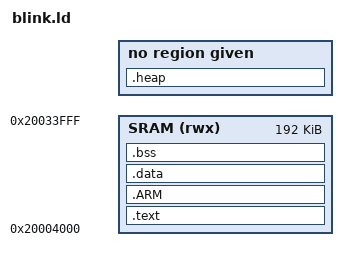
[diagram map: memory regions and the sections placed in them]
/*
 *  Copyright (c) 2015, Parse, LLC. All rights reserved.
 *
 *  You are hereby granted a non-exclusive, worldwide, royalty-free license to use,
 *  copy, modify, and distribute this software in source code or binary form for use
 *  in connection with the web services and APIs provided by Parse.
 *
 *  As with any software that integrates with the Parse platform, your use of
 *  this software is subject to the Parse Terms of Service
 *  [https://www.parse.com/about/terms]. This copyright notice shall be
 *  included in all copies or substantial portions of the software.
 *
 *  THE SOFTWARE IS PROVIDED "AS IS", WITHOUT WARRANTY OF ANY KIND, EXPRESS OR
 *  IMPLIED, INCLUDING BUT NOT LIMITED TO THE WARRANTIES OF MERCHANTABILITY, FITNESS
 *  FOR A PARTICULAR PURPOSE AND NONINFRINGEMENT. IN NO EVENT SHALL THE AUTHORS OR
 *  COPYRIGHT HOLDERS BE LIABLE FOR ANY CLAIM, DAMAGES OR OTHER LIABILITY, WHETHER
 *  IN AN ACTION OF CONTRACT, TORT OR OTHERWISE, ARISING FROM, OUT OF OR IN
 *  CONNECTION WITH THE SOFTWARE OR THE USE OR OTHER DEALINGS IN THE SOFTWARE.
 *
 */

/*
 * GCC Linker script for Blink application.
 */

HEAP_SIZE = 0x00010000;

MEMORY {
    SRAM (rwx) : ORIGIN = 0x20004000, LENGTH = 0x00030000
}

SECTIONS {
    .text : {
        _text = .;
        KEEP(*(.intvecs))
        *(.text*)
        *(.rodata*)
        *(.ARM.extab* .gnu.linkonce.armextab.*)
        . = ALIGN(8);
        _etext = .;
    } > SRAM

    .ARM : {
        __exidx_start = .;
        *(.ARM.exidx*)
        __exidx_end = .;
    } > SRAM

    __init_data = .;

    .data : AT(__init_data) {
        _data = .;
        *(.data*)
        . = ALIGN (8);
        _edata = .;
    } > SRAM

    .bss : {
        _bss = .;
        *(.bss*)
        *(COMMON)
        _ebss = .;
    } > SRAM

    .heap : {
        _heap = .;
        . = . + HEAP_SIZE;
        . = ALIGN(8);
        _eheap = .;
    }
}
